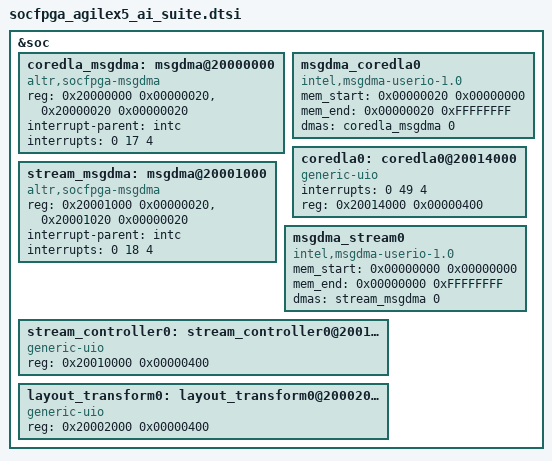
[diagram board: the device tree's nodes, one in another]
// SPDX-License-Identifier: GPL-2.0-only
/*
 * Copyright (C) 2023, Intel Corporation
 */
 
 &soc {
 	coredla_msgdma: msgdma@20000000 {
		status = "okay";
		compatible = "altr,socfpga-msgdma";
		reg = <0x20000000 0x00000020>,
			  <0x20000020 0x00000020>;
		reg-names = "csr", "desc";
		interrupt-parent = <&intc>;
		interrupts = <0 17 4>;
		#dma-cells = <1>;
	};

	msgdma_coredla0 {
		status = "okay";
		compatible = "intel,msgdma-userio-1.0";
		#address-cells = <2>;
		mem_start = <0x00000020 0x00000000>;
		mem_end = <0x00000020 0xFFFFFFFF>;
		reg-names = "emif";
		dmas = <&coredla_msgdma 0>;
		dma-names = "rx-tx";
	};

	coredla0:coredla0@20014000 {
		status = "okay";
		compatible = "generic-uio";
		interrupts = <0 49 4>;
		reg = <0x20014000 0x00000400>;
	};

	stream_msgdma: msgdma@20001000 {
		status = "okay";
		compatible = "altr,socfpga-msgdma";
		reg = <0x20001000 0x00000020>,
			  <0x20001020 0x00000020>;
		reg-names = "csr", "desc";
		interrupt-parent = <&intc>;
		interrupts = <0 18 4>;
		#dma-cells = <1>;
	};

	msgdma_stream0 {
		status = "okay";
		compatible = "intel,msgdma-userio-1.0";
		#address-cells = <2>;
		mem_start = <0x00000000 0x00000000>;
		mem_end = <0x00000000 0xFFFFFFFF>;
		reg-names = "emif";
		dmas = <&stream_msgdma 0>;
		dma-names = "tx";
	};

	stream_controller0:stream_controller0@20010000 {
		status = "okay";
		compatible = "generic-uio";
		reg = <0x20010000 0x00000400>;
	};

	layout_transform0:layout_transform0@20002000 {
		status = "okay";
		compatible = "generic-uio";
		reg = <0x20002000 0x00000400>;
	};
 };


